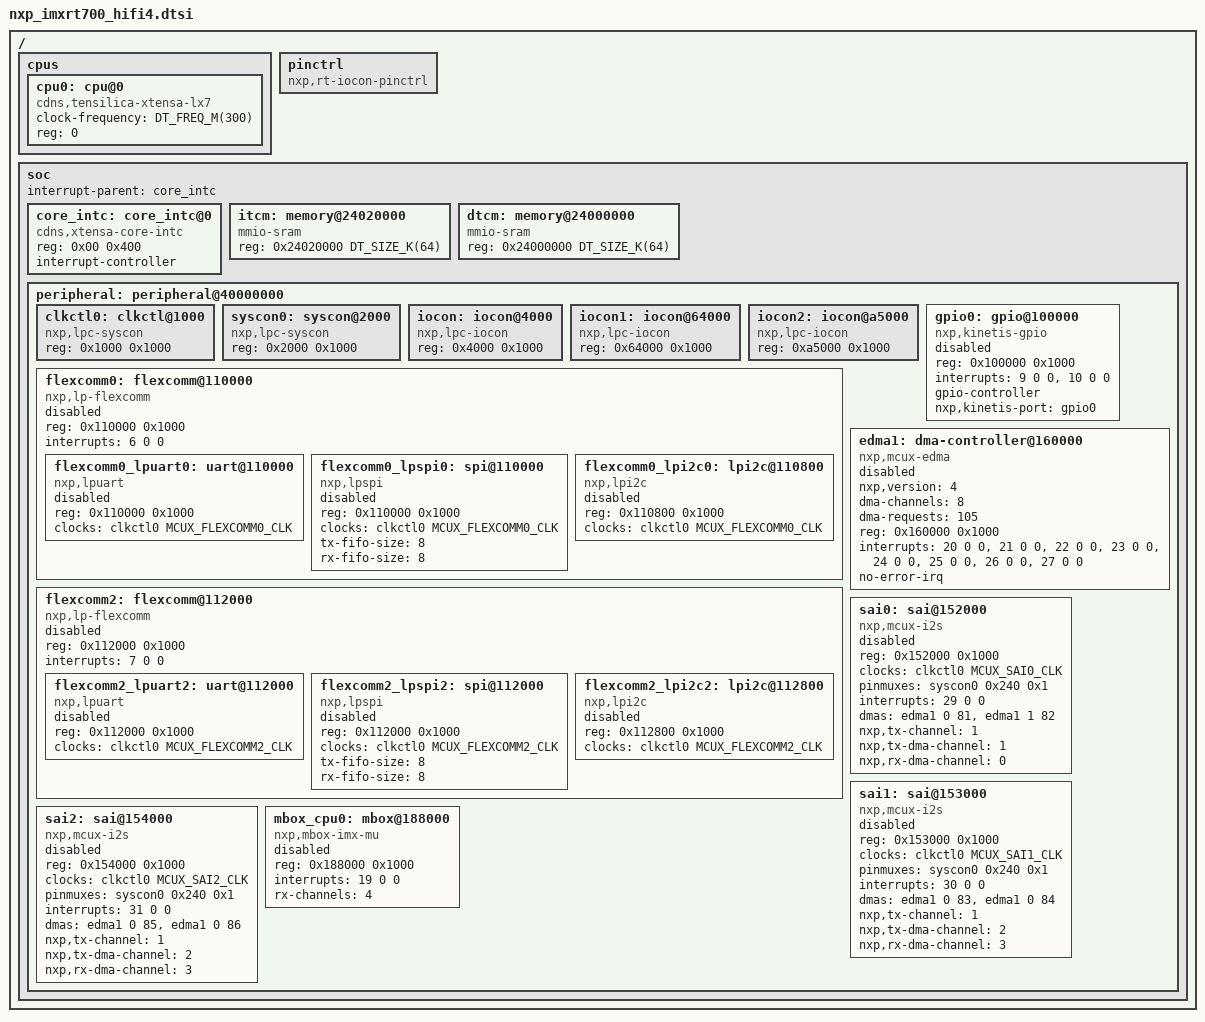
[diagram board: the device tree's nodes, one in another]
/*
 * Copyright 2024-2025 NXP
 *
 * SPDX-License-Identifier: Apache-2.0
 */

#include <xtensa/xtensa.dtsi>
#include <freq.h>
#include <mem.h>
#include <zephyr/dt-bindings/clock/mcux_lpc_syscon_clock.h>

/ {
	cpus {
		#address-cells = <1>;
		#size-cells = <0>;

		cpu0: cpu@0 {
			device_type = "cpu";
			compatible = "cdns,tensilica-xtensa-lx7";
			clock-frequency = <DT_FREQ_M(300)>;
			reg = <0>;
		};
	};

	pinctrl: pinctrl {
		compatible = "nxp,rt-iocon-pinctrl";
	};

	soc {
		interrupt-parent = <&core_intc>;

		/*
		 * Dummy interrupt controller node - IRQs are handled directly by platform code.
		 * INPUTMUX (IRQ allocation) is set up in mimxrt685s/hifi4 soc.c.
		 */
		core_intc: core_intc@0 {
			compatible = "cdns,xtensa-core-intc";
			reg = <0x00 0x400>;
			interrupt-controller;
			#interrupt-cells = <3>;
		};

		itcm: memory@24020000 {
			device_type = "memory";
			compatible = "mmio-sram";
			reg = <0x24020000 DT_SIZE_K(64)>;
		};

		dtcm: memory@24000000 {
			device_type = "memory";
			compatible = "mmio-sram";
			reg = <0x24000000 DT_SIZE_K(64)>;
		};

		peripheral: peripheral@40000000 {
			ranges = <0x0 0x40000000 0x10000000>;

			#address-cells = <1>;
    		#size-cells = <1>;
		};
	};
};

&peripheral {
	clkctl0: clkctl@1000 {
		compatible = "nxp,lpc-syscon";
		reg = <0x1000 0x1000>;
		#clock-cells = <1>;
	};

	syscon0: syscon@2000 {
		compatible = "nxp,lpc-syscon";
		reg = <0x2000 0x1000>;
		#clock-cells = <1>;
		#pinmux-cells = <2>;
	};

	iocon: iocon@4000 {
		compatible = "nxp,lpc-iocon";
		reg = <0x4000 0x1000>;
		status = "okay";
	};

	iocon1: iocon@64000 {
		compatible = "nxp,lpc-iocon";
		reg = <0x64000 0x1000>;
		status = "okay";
	};

	iocon2: iocon@a5000 {
		compatible = "nxp,lpc-iocon";
		reg = <0xa5000 0x1000>;
		status = "okay";
	};

	gpio0: gpio@100000 {
		compatible = "nxp,kinetis-gpio";
		status = "disabled";
		reg = <0x100000 0x1000>;
		interrupts = <9 0 0>, <10 0 0>;
		gpio-controller;
		#gpio-cells = <2>;
		nxp,kinetis-port = <&gpio0>;
	};

	flexcomm0: flexcomm@110000 {
		compatible = "nxp,lp-flexcomm";
		reg = <0x110000 0x1000>;
		interrupts = <6 0 0>;
		status = "disabled";

		/* Empty ranges property implies parent and child address space is identical */
		ranges = <>;
		#address-cells = <1>;
		#size-cells = <1>;

		flexcomm0_lpuart0: uart@110000 {
			compatible = "nxp,lpuart";
			reg = <0x110000 0x1000>;
			clocks = <&clkctl0 MCUX_FLEXCOMM0_CLK>;
			status = "disabled";
		};

		flexcomm0_lpspi0: spi@110000 {
			compatible = "nxp,lpspi";
			reg = <0x110000 0x1000>;
			clocks = <&clkctl0 MCUX_FLEXCOMM0_CLK>;
			#address-cells = <1>;
			#size-cells = <0>;
			tx-fifo-size = <8>;
			rx-fifo-size = <8>;
			status = "disabled";
		};

		flexcomm0_lpi2c0: lpi2c@110800 {
			compatible = "nxp,lpi2c";
			reg = <0x110800 0x1000>;
			clocks = <&clkctl0 MCUX_FLEXCOMM0_CLK>;
			#address-cells = <1>;
			#size-cells = <0>;
			status = "disabled";
		};
	};

	flexcomm2: flexcomm@112000 {
		compatible = "nxp,lp-flexcomm";
		reg = <0x112000 0x1000>;
		interrupts = <7 0 0>;
		status = "disabled";

		/* Empty ranges property implies parent and child address space is identical */
		ranges = <>;
		#address-cells = <1>;
		#size-cells = <1>;

		flexcomm2_lpuart2: uart@112000 {
			compatible = "nxp,lpuart";
			reg = <0x112000 0x1000>;
			clocks = <&clkctl0 MCUX_FLEXCOMM2_CLK>;
			status = "disabled";
		};

		flexcomm2_lpspi2: spi@112000 {
			compatible = "nxp,lpspi";
			reg = <0x112000 0x1000>;
			clocks = <&clkctl0 MCUX_FLEXCOMM2_CLK>;
			#address-cells = <1>;
			#size-cells = <0>;
			tx-fifo-size = <8>;
			rx-fifo-size = <8>;
			status = "disabled";
		};

		flexcomm2_lpi2c2: lpi2c@112800 {
			compatible = "nxp,lpi2c";
			reg = <0x112800 0x1000>;
			clocks = <&clkctl0 MCUX_FLEXCOMM2_CLK>;
			#address-cells = <1>;
			#size-cells = <0>;
			status = "disabled";
		};
	};
	
	edma1: dma-controller@160000 {
		#dma-cells = <2>;
		compatible = "nxp,mcux-edma";
		nxp,version = <4>;
		dma-channels = <8>;
		dma-requests = <105>;
		reg = <0x160000 0x1000>;
		interrupts = <20 0 0>, <21 0 0>, <22 0 0>, <23 0 0>,
			<24 0 0>, <25 0 0>, <26 0 0>, <27 0 0>;
		no-error-irq;
		status = "disabled";
	};

	sai0: sai@152000 {
		compatible = "nxp,mcux-i2s";
		#address-cells = <1>;
		#size-cells = <0>;
		#pinmux-cells = <2>;
		reg = < 0x152000 0x1000>;
		clocks = <&clkctl0 MCUX_SAI0_CLK>;
		pinmuxes = <&syscon0 0x240 0x1>;
		interrupts = <29 0 0>;
		dmas = <&edma1 0 81>, <&edma1 1 82>;
		dma-names = "rx", "tx";
		nxp,tx-channel = <1>;
		nxp,tx-dma-channel = <1>;
		nxp,rx-dma-channel = <0>;
		status = "disabled";
	};

	sai1: sai@153000 {
		compatible = "nxp,mcux-i2s";
		#address-cells = <1>;
		#size-cells = <0>;
		#pinmux-cells = <2>;
		reg = < 0x153000 0x1000>;
		clocks = <&clkctl0 MCUX_SAI1_CLK>;
		pinmuxes = <&syscon0 0x240 0x1>;
		interrupts = <30 0 0>;
		dmas = <&edma1 0 83>, <&edma1 0 84>;
		dma-names = "rx", "tx";
		nxp,tx-channel = <1>;
		nxp,tx-dma-channel = <2>;
		nxp,rx-dma-channel = <3>;
		status = "disabled";
	};

	sai2: sai@154000 {
		compatible = "nxp,mcux-i2s";
		#address-cells = <1>;
		#size-cells = <0>;
		#pinmux-cells = <2>;
		reg = < 0x154000 0x1000>;
		clocks = <&clkctl0 MCUX_SAI2_CLK>;
		pinmuxes = <&syscon0 0x240 0x1>;
		interrupts = <31 0 0>;
		dmas = <&edma1 0 85>, <&edma1 0 86>;
		dma-names = "rx", "tx";
		nxp,tx-channel = <1>;
		nxp,tx-dma-channel = <2>;
		nxp,rx-dma-channel = <3>;
		status = "disabled";
	};

	mbox_cpu0: mbox@188000 {
		#mbox-cells = <1>;

		compatible = "nxp,mbox-imx-mu";
		reg = <0x188000 0x1000>;

		interrupts = <19 0 0>;
		rx-channels = <4>;

		status = "disabled";
	};
};
